# ATSAMD21G17L register map
Vendor: Microchip Technology Inc.; Series: SAMD21; File version: G
CPU: CM0+ r0p1, little endian, no MPU, no FPU, VTOR, 2 interrupt priority bits, 30 interrupts
Registers are 32-bit, read-write, reset 0x0 unless marked. A register's access mark holds for its fields unless they carry their own. Offsets are from the block's base; [hi:lo] are bit positions; {n}, {i} and the like mark numbered series; 'fields as' and 'values as' point back to an identical list; <NAME> marks a mode.

## ADC — Analog Digital Converter
Base 0x42004000; register names take the prefix ADC_
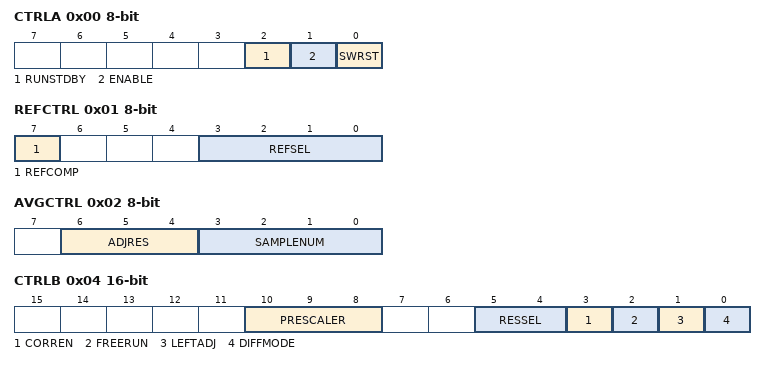
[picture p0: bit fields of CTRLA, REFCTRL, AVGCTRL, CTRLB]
0x00 CTRLA 8-bit — Control A
  [2] RUNSTDBY — Run in Standby
  [1] ENABLE
  [0] SWRST — Software Reset
0x01 REFCTRL 8-bit — Reference Control
  [7] REFCOMP — Reference Buffer Offset Compensation Enable
  [3:0] REFSEL — Reference Selection
    0=INT1V (1.0V voltage reference); 1=INTVCC0 (1/1.48 VDDANA); 2=INTVCC1 (1/2 VDDANA (only for VDDANA > 2.0V)); 3=AREFA (External reference); 4=AREFB (External reference)
0x02 AVGCTRL 8-bit — Average Control
  [6:4] ADJRES — Adjusting Result / Division Coefficient
  [3:0] SAMPLENUM — Number of Samples to be Collected
    0=1 sample; 1=2 samples; 2=4 samples; 3=8 samples; 4=16 samples; 5=32 samples; 6=64 samples; 7=128 samples; 8=256 samples; 9=512 samples; 10=1024 samples
0x03 SAMPCTRL 8-bit — Sampling Time Control
  [5:0] SAMPLEN — Sampling Time Length
0x04 CTRLB 16-bit — Control B
  [10:8] PRESCALER — Prescaler Configuration
    0=DIV4 (Peripheral clock divided by 4); 1=DIV8 (Peripheral clock divided by 8); 2=DIV16 (Peripheral clock divided by 16); 3=DIV32 (Peripheral clock divided by 32); 4=DIV64 (Peripheral clock divided by 64); 5=DIV128 (Peripheral clock divided by 128); 6=DIV256 (Peripheral clock divided by 256); 7=DIV512 (Peripheral clock divided by 512)
  [5:4] RESSEL — Conversion Result Resolution
    0=12BIT (12-bit result); 1=16BIT (For averaging mode output); 2=10BIT (10-bit result); 3=8BIT (8-bit result)
  [3] CORREN — Digital Correction Logic Enabled
  [2] FREERUN — Free Running Mode
  [1] LEFTADJ — Left-Adjusted Result
  [0] DIFFMODE — Differential Mode
0x08 WINCTRL 8-bit — Window Monitor Control
  [2:0] WINMODE — Window Monitor Mode
    0=DISABLE (No window mode (default)); 1=MODE1 (Mode 1: RESULT > WINLT); 2=MODE2 (Mode 2: RESULT < WINUT); 3=MODE3 (Mode 3: WINLT < RESULT < WINUT); 4=MODE4 (Mode 4: !(WINLT < RESULT < WINUT))
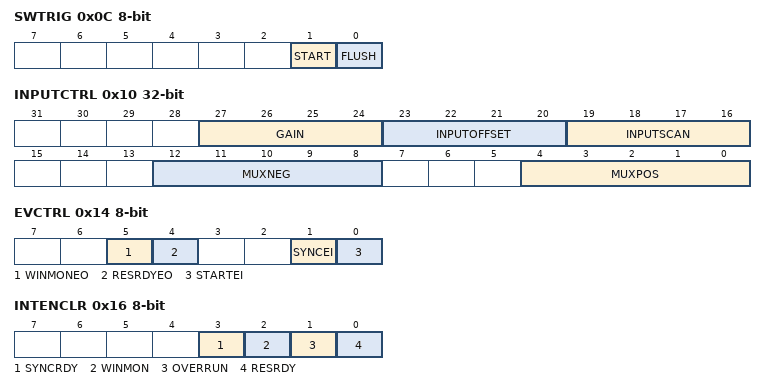
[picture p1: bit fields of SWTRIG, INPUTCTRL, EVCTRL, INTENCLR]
0x0C SWTRIG 8-bit — Software Trigger
  [1] START — ADC Start Conversion
  [0] FLUSH — ADC Conversion Flush
0x10 INPUTCTRL — Input Control
  [27:24] GAIN — Gain Factor Selection
    0=1X; 1=2X; 2=4X; 3=8X; 4=16X; 15=DIV2 (1/2x)
  [23:20] INPUTOFFSET — Positive Mux Setting Offset
  [19:16] INPUTSCAN — Number of Input Channels Included in Scan
  [12:8] MUXNEG — Negative Mux Input Selection
    {v}=PIN{v} (ADC AIN{v} Pin) (v=0..7); 24=GND (Internal Ground); 25=IOGND (I/O Ground)
  [4:0] MUXPOS — Positive Mux Input Selection
    {v}=PIN{v} (ADC AIN{v} Pin) (v=0..19); 24=TEMP (Temperature Reference); 25=BANDGAP (Bandgap Voltage); 26=SCALEDCOREVCC (1/4 Scaled Core Supply); 27=SCALEDIOVCC (1/4 Scaled I/O Supply); 28=DAC (DAC Output)
0x14 EVCTRL 8-bit — Event Control
  [5] WINMONEO — Window Monitor Event Out
  [4] RESRDYEO — Result Ready Event Out
  [1] SYNCEI — Synchronization Event In
  [0] STARTEI — Start Conversion Event In
0x16 INTENCLR 8-bit — Interrupt Enable Clear
  [3] SYNCRDY — Synchronization Ready Interrupt Enable
  [2] WINMON — Window Monitor Interrupt Enable
  [1] OVERRUN — Overrun Interrupt Enable
  [0] RESRDY — Result Ready Interrupt Enable
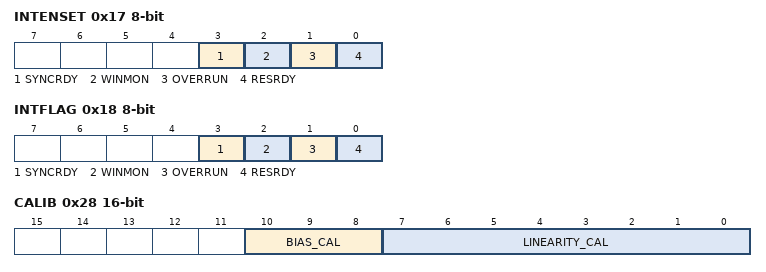
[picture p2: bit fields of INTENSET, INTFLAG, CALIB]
0x17 INTENSET 8-bit — Interrupt Enable Set
  fields as INTENCLR
0x18 INTFLAG 8-bit — Interrupt Flag Status and Clear
  [3] SYNCRDY write-1-clears — Synchronization Ready
  [2] WINMON write-1-clears — Window Monitor
  [1] OVERRUN write-1-clears
  [0] RESRDY write-1-clears — Result Ready
0x19 STATUS 8-bit ro
  [7] SYNCBUSY — Synchronization Busy
0x1A RESULT 16-bit ro
  [15:0] RESULT — Result Conversion Value
0x1C WINLT 16-bit — Window Monitor Lower Threshold
  [15:0] WINLT — Window Lower Threshold
0x20 WINUT 16-bit — Window Monitor Upper Threshold
  [15:0] WINUT — Window Upper Threshold
0x24 GAINCORR 16-bit — Gain Correction
  [11:0] GAINCORR — Gain Correction Value
0x26 OFFSETCORR 16-bit — Offset Correction
  [11:0] OFFSETCORR — Offset Correction Value
0x28 CALIB 16-bit — Calibration
  [10:8] BIAS_CAL — Bias Calibration Value
  [7:0] LINEARITY_CAL — Linearity Calibration Value
0x2A DBGCTRL 8-bit — Debug Control
  [0] DBGRUN — Debug Run

## Notices in the file
Copyright (c) 2018 Microchip Technology Inc.
SPDX-License-Identifier: Apache-2.0
Licensed under the Apache License, Version 2.0 (the "License");
you may not use this file except in compliance with the License.
You may obtain a copy of the License at
http://www.apache.org/licenses/LICENSE-2.0
Unless required by applicable law or agreed to in writing, software
distributed under the License is distributed on an "AS IS" BASIS,
WITHOUT WARRANTIES OR CONDITIONS OF ANY KIND, either express or implied.
See the License for the specific language governing permissions and
limitations under the License.
